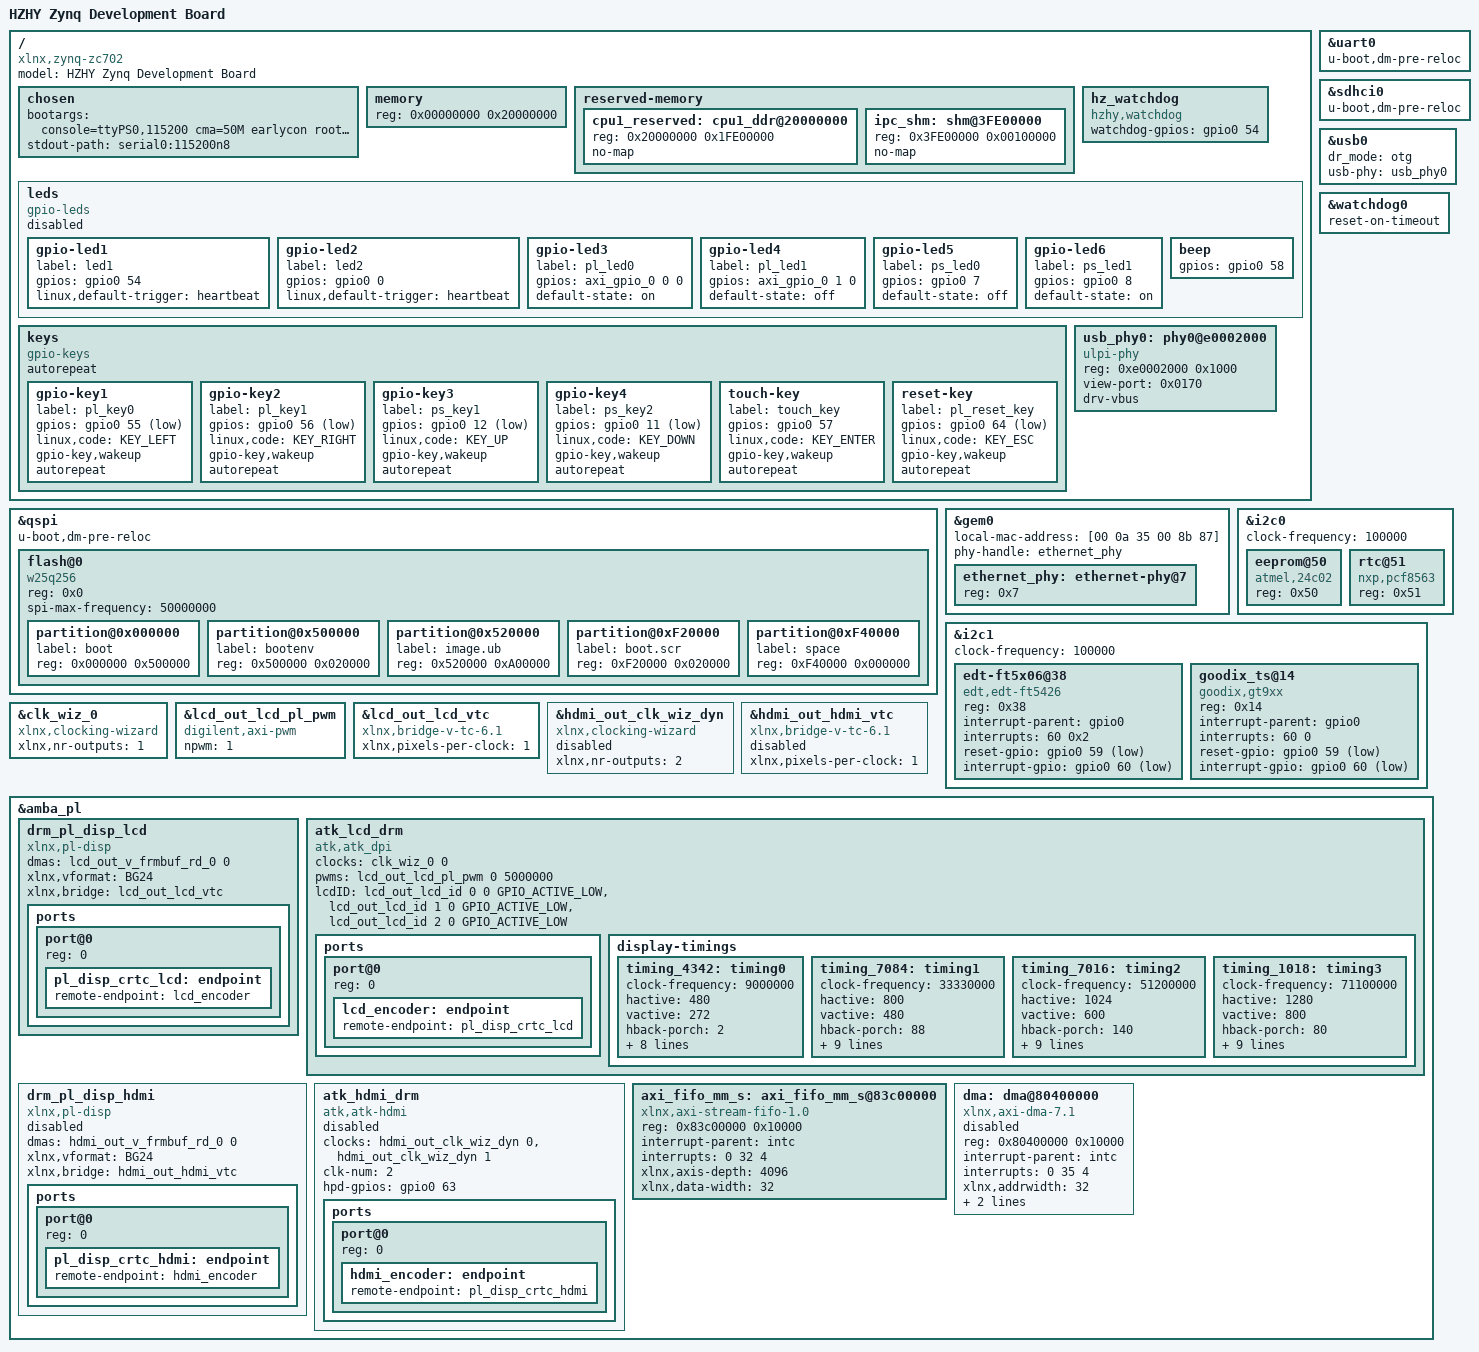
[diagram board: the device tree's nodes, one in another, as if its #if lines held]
/include/ "system-conf.dtsi"
/ {
};
#include <dt-bindings/gpio/gpio.h>
#include <dt-bindings/input/input.h>
#include <dt-bindings/media/xilinx-vip.h>
#include <dt-bindings/phy/phy.h>
/ {
	model = "HZHY Zynq Development Board";
	compatible = "xlnx,zynq-zc702", "xlnx,zynq-7000";
	chosen {
		bootargs = "console=ttyPS0,115200 cma=50M earlycon root=/dev/mmcblk0p2 rw rootwait";
		stdout-path = "serial0:115200n8";
	};
	/* --- 限制 Linux 只看到低 512MB 内存 --- */
	memory {
		device_type = "memory";
		reg = <0x00000000 0x20000000>;	// 0~0x1FFFFFFF
	};
reserved-memory {
    #address-cells = <1>;
    #size-cells = <1>;
    ranges;

    cpu1_reserved: cpu1_ddr@20000000 {
        reg = <0x20000000 0x1FE00000>;   // 0x20000000 ~ 0x3FE00000（510MB）
        no-map;
    };

    ipc_shm: shm@3FE00000 {
        reg = <0x3FE00000 0x00100000>;   // 0x3FE00000 ~ 0x3FF00000
        no-map;
    };
};
#ifdef CONFIG_VERSION_WDG
	hz_watchdog:hz_watchdog{
		compatible = "hzhy,watchdog";
		watchdog-gpios = <&gpio0 54 GPIO_ACTIVE_HIGH>;
		status = "okay";
	};
#endif
	leds: leds {
		compatible = "gpio-leds";
		status = "disabled";
#ifndef CONFIG_VERSION_WDG
		gpio-led1 {
			label = "led1";
			gpios = <&gpio0 54 GPIO_ACTIVE_HIGH>;
			linux,default-trigger = "heartbeat";
			status = "okay";
		};
#endif
		gpio-led2 {
			label = "led2";
			gpios = <&gpio0 0 GPIO_ACTIVE_HIGH>;
			linux,default-trigger = "heartbeat";
		};
		gpio-led3 {
			label = "pl_led0";
			gpios = <&axi_gpio_0 0 0 GPIO_ACTIVE_HIGH>;
			default-state = "on";
		};
		gpio-led4 {
			label = "pl_led1";
			gpios = <&axi_gpio_0 1 0 GPIO_ACTIVE_HIGH>;
			default-state = "off";
		};
		gpio-led5 {
			label = "ps_led0";
			gpios = <&gpio0 7 GPIO_ACTIVE_HIGH>;
			default-state = "off";
		};
		gpio-led6 {
			label = "ps_led1";
			gpios = <&gpio0 8 GPIO_ACTIVE_HIGH>;
			default-state = "on";
		};
		beep {
			gpios = <&gpio0 58 GPIO_ACTIVE_HIGH>;
		};
	};
	keys:keys {
		compatible = "gpio-keys";
		autorepeat;
		status = "okay";
		gpio-key1 {
			label = "pl_key0";
			gpios = <&gpio0 55 GPIO_ACTIVE_LOW>;
			linux,code = <KEY_LEFT>;
			gpio-key,wakeup;
			autorepeat;
		};
		gpio-key2 {
			label = "pl_key1";
			gpios = <&gpio0 56 GPIO_ACTIVE_LOW>;
			linux,code = <KEY_RIGHT>;
			gpio-key,wakeup;
			autorepeat;
		};
		gpio-key3 {
			label = "ps_key1";
			gpios = <&gpio0 12 GPIO_ACTIVE_LOW>;
			linux,code = <KEY_UP>;
			gpio-key,wakeup;
			autorepeat;
		};
		gpio-key4 {
			label = "ps_key2";
			gpios = <&gpio0 11 GPIO_ACTIVE_LOW>;
			linux,code = <KEY_DOWN>;
			gpio-key,wakeup;
			autorepeat;
		};
		touch-key {
			label = "touch_key";
			gpios = <&gpio0 57 GPIO_ACTIVE_HIGH>;
			linux,code = <KEY_ENTER>;
			gpio-key,wakeup;
			autorepeat;
		};
		reset-key {
			label = "pl_reset_key";
			gpios = <&gpio0 64 GPIO_ACTIVE_LOW>;
			linux,code = <KEY_ESC>;
			gpio-key,wakeup;
			autorepeat;
		};
	};
	usb_phy0: phy0@e0002000 {
		compatible = "ulpi-phy";
		#phy-cells = <0>;
		reg = <0xe0002000 0x1000>;
		view-port = <0x0170>;
		drv-vbus;
	};
};
&uart0 {
	u-boot,dm-pre-reloc;
	status = "okay";
};
&sdhci0 {
	u-boot,dm-pre-reloc;
	status = "okay";
};
&usb0 {
	dr_mode = "otg";
	usb-phy = <&usb_phy0>;
};
&qspi {
	u-boot,dm-pre-reloc;
	flash@0 { /* 16 MB */
		compatible = "w25q256", "jedec,spi-nor";
		reg = <0x0>;
		spi-max-frequency = <50000000>;
		#address-cells = <1>;
		#size-cells = <1>;
		partition@0x000000 {
			label = "boot";
			reg = <0x000000 0x500000>;
		};
		partition@0x500000 {
			label = "bootenv";
			reg = <0x500000 0x020000>;
		};
		partition@0x520000 {
			label = "image.ub";
			reg = <0x520000 0xA00000>;
		};
		partition@0xF20000 {
			label = "boot.scr";
			reg = <0xF20000 0x020000>;
		};
		partition@0xF40000 {
			label = "space";
			reg = <0xF40000 0x000000>;
		};
	};
};
&gem0 {
	local-mac-address = [00 0a 35 00 8b 87];
	phy-handle = <&ethernet_phy>;
	ethernet_phy: ethernet-phy@7 {	/* yt8521 */
		reg = <0x7>;
		device_type = "ethernet-phy";
	};
};
&watchdog0 {
	status = "okay";
	reset-on-timeout;
};
&i2c0 {
	clock-frequency = <100000>;
	eeprom@50 {
		compatible = "atmel,24c02";
		reg = <0x50>;
	};
	rtc@51 {
		compatible = "nxp,pcf8563";
		reg = <0x51>;
	};
};
&i2c1 {
	clock-frequency = <100000>;
	edt-ft5x06@38 {
		compatible = "edt,edt-ft5426";
		reg = <0x38>;
		interrupt-parent = <&gpio0>;
		interrupts = <60 0x2>;
		reset-gpio = <&gpio0 59 GPIO_ACTIVE_LOW>;
		interrupt-gpio = <&gpio0 60 GPIO_ACTIVE_LOW>;
	};
	goodix_ts@14 {
		compatible = "goodix,gt9xx";
		status = "okay";
		reg = <0x14>;
		interrupt-parent = <&gpio0>;
		interrupts = <60 0>;
		reset-gpio = <&gpio0 59 GPIO_ACTIVE_LOW>;
		interrupt-gpio = <&gpio0 60 GPIO_ACTIVE_LOW>;
	};
};
// &i2c2 {
// 	status = "disabled";
	// clock-frequency = <100000>;
	// ov5640@3c {
	// 	compatible = "ovti,ov5640";
	// 	reg = <0x3c>;
	// 	pwdn-gpios = <&gpio0 61 GPIO_ACTIVE_HIGH>;
	// 	reset-gpios = <&gpio0 62 GPIO_ACTIVE_LOW>;
	// 	status = "okay";
	// 	#address-cells = <1>;
	// 	#size-cells = <0>;
	// 	port@0 {
	// 		reg = <0>;
	// 		ov5640_ep: endpoint {
	// 			remote-endpoint = <&xlnx_vcap>;
	// 		};
	// 	};
	// };
// };
&clk_wiz_0 {
	compatible = "xlnx,clocking-wizard";
	xlnx,nr-outputs = <1>;
};
&lcd_out_lcd_pl_pwm{
	compatible = "digilent,axi-pwm";
	#pwm-cells = <2>;
	clock-names = "pwm";
	npwm = <1>;
};
&lcd_out_lcd_vtc {
	compatible = "xlnx,bridge-v-tc-6.1";
	xlnx,pixels-per-clock = <1>;
};
&hdmi_out_clk_wiz_dyn{
	status = "disabled";
	compatible = "xlnx,clocking-wizard";
	xlnx,nr-outputs = <2>;
};
&hdmi_out_hdmi_vtc {
	status = "disabled";
	compatible = "xlnx,bridge-v-tc-6.1";
	xlnx,pixels-per-clock = <1>;
};
&amba_pl {
	drm_pl_disp_lcd {
		compatible = "xlnx,pl-disp";
		dmas = <&lcd_out_v_frmbuf_rd_0 0>;
		dma-names = "dma0";
		xlnx,vformat = "BG24";
		xlnx,bridge = <&lcd_out_lcd_vtc>;
		ports {
			#address-cells = <1>;
			#size-cells = <0>;
			port@0 {
				reg = <0>;
				pl_disp_crtc_lcd:endpoint {
					remote-endpoint = <&lcd_encoder>;
				};
			};
		};
	};
	atk_lcd_drm{
		compatible = "atk,atk_dpi";
		status = "okay";
		clocks = <&clk_wiz_0 0>;
		clock-names = "lcd_pclk";
		pwms = <&lcd_out_lcd_pl_pwm 0 5000000>;
		lcdID = <&lcd_out_lcd_id 0 0 GPIO_ACTIVE_LOW
			&lcd_out_lcd_id 1 0 GPIO_ACTIVE_LOW
			&lcd_out_lcd_id 2 0 GPIO_ACTIVE_LOW>;
		ports {
			#address-cells = <1>;
			#size-cells = <0>;
			port@0 {
				reg = <0>;
				lcd_encoder: endpoint {
					remote-endpoint = <&pl_disp_crtc_lcd>;
				};
			};
		};
		display-timings {
			timing_4342: timing0 {
				clock-frequency = <9000000>;
				hactive = <480>;
				vactive = <272>;
				hback-porch = <2>;
				hfront-porch = <2>;
				hsync-len = <41>;
				vback-porch = <2>;
				vfront-porch = <2>;
				vsync-len = <10>;
				hsync-active = <0>;
				vsync-active = <0>;
				de-active = <1>;
			};
			timing_7084: timing1 {
				clock-frequency = <33330000>;
				hactive = <800>;
				vactive = <480>;
				hback-porch = <88>;
				hfront-porch = <40>;
				hsync-len = <128>;
				vback-porch = <33>;
				vfront-porch = <10>;
				vsync-len = <2>;
				hsync-active = <0>;
				vsync-active = <0>;
				de-active = <1>;
				pixelclk-active = <0>;
			};
			timing_7016: timing2 {
				clock-frequency = <51200000>;
				hactive = <1024>;
				vactive = <600>;
				hback-porch = <140>;
				hfront-porch = <160>;
				hsync-len = <20>;
				vback-porch = <20>;
				vfront-porch = <12>;
				vsync-len = <3>;
				hsync-active = <0>;
				vsync-active = <0>;
				de-active = <1>;
				pixelclk-active = <0>;
			};
			timing_1018: timing3 {
				clock-frequency = <71100000>;
				hactive = <1280>;
				vactive = <800>;
				hback-porch = <80>;
				hfront-porch = <70>;
				hsync-len = <10>;
				vback-porch = <10>;
				vfront-porch = <10>;
				vsync-len = <3>;
				hsync-active = <0>;
				vsync-active = <0>;
				de-active = <1>;
				pixelclk-active = <0>;
			};
		};
	};
	/* === HDMI 完全禁用 === */
	drm_pl_disp_hdmi {
		status = "disabled";
		compatible = "xlnx,pl-disp";
		dmas = <&hdmi_out_v_frmbuf_rd_0 0>;
		dma-names = "dma0";
		xlnx,vformat = "BG24";
		xlnx,bridge = <&hdmi_out_hdmi_vtc>;
		ports {
			#address-cells = <1>;
			#size-cells = <0>;
			port@0 {
				reg = <0>;
				pl_disp_crtc_hdmi:endpoint {
					remote-endpoint = <&hdmi_encoder>;
				};
			};
		};
	};
	atk_hdmi_drm{
		status = "disabled";
		compatible = "atk,atk-hdmi";
		clocks = <&hdmi_out_clk_wiz_dyn 0>, <&hdmi_out_clk_wiz_dyn 1>;
		clock-names = "hdmi_pclk", "hdmi_pclk_5x";
		clk-num = <2>;
		/* ddc-i2c-bus 已移除，HDMI 不再占用 I2C1 */
		hpd-gpios = <&gpio0 63 GPIO_ACTIVE_HIGH>;
		ports {
			#address-cells = <1>;
			#size-cells = <0>;
			port@0 {
				reg = <0>;
				hdmi_encoder: endpoint {
					remote-endpoint = <&pl_disp_crtc_hdmi>;
				};
			};
		};
	};
	/* 摄像头 vcap_dvp 因 i2c2 被注释且 ov5640_ep 不存在，暂时注释以免编译失败 */
	// vcap_dvp {
	// 	compatible = "xlnx,video";
	// 	dmas = <&camera_in_v_frmbuf_wr_0 0>;
	// 	dma-names = "port0";
	// 	status = "okay";
	// 	ports {
	// 		#address-cells = <1>;
	// 		#size-cells = <0>;
	// 		port@0 {
	// 			reg = <0>;
	// 			direction = "input";
	// 			xlnx_vcap: endpoint {
	// 				remote-endpoint = <&ov5640_ep>;
	// 			};
	// 		};
	// 	};
	// };
	/* ===== 新增：AXI Stream FIFO 控制 DDS（中断 3） ===== */
	axi_fifo_mm_s: axi_fifo_mm_s@83c00000 {
		compatible = "xlnx,axi-stream-fifo-1.0", "xlnx,axi-stream-fifo";
		reg = <0x83c00000 0x10000>;
		interrupt-parent = <&intc>;
		interrupts = <0 32 4>;   /* IRQ_F2P[3] → GIC SPI 64 */
		xlnx,axis-depth = <4096>;
		xlnx,data-width = <32>;
		status = "okay";
	};
	/* ===== 新增：AXI DMA 接收高速 AD 数据（中断 6） ===== */
	dma: dma@80400000 {
		compatible = "xlnx,axi-dma-7.1", "xlnx,axi-dma";
		reg = <0x80400000 0x10000>;
		interrupt-parent = <&intc>;
		interrupts = <0 35 4>;   /* IRQ_F2P[6] → GIC SPI 67 */
		#dma-cells = <1>;
		xlnx,addrwidth = <32>;
		xlnx,datawidth = <0x20>;
		dma-channels = <1>;
		status = "disabled";
	};
};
